# CSI_TX_IF0_CP_INTD_CFG_INTD_CFG register map
Vendor: Texas Instruments
Peripheral module from a debugger description file (folder J7ES).
Registers are 32-bit, access not given, reset values left out (the file's numbers can be read two ways) unless marked. A register's access mark holds for its fields unless they carry their own. Offsets are as the file gives them; lines under a group give offsets from that group; [hi:lo] are bit positions; {n}, {i} and the like mark numbered series; 'fields as' and 'values as' point back to an identical list; <NAME> marks a mode.

## CSI_TX_IF0_CP_INTD_CFG_INTD_CFG
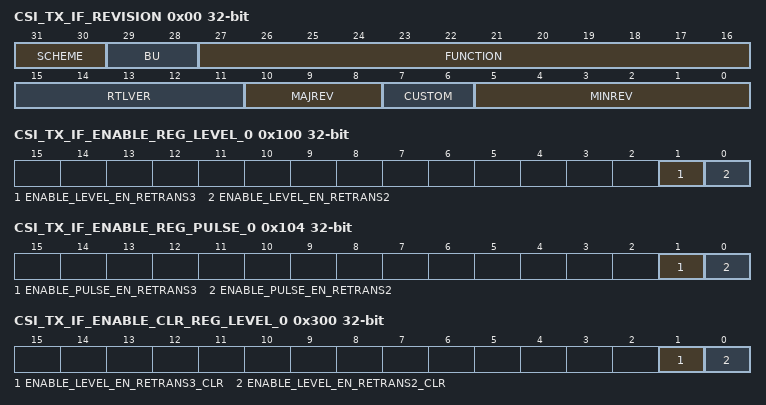
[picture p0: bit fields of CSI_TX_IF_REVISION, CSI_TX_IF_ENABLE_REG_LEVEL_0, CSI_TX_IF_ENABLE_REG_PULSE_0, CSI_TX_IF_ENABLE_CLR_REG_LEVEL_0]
0x00 CSI_TX_IF_REVISION ro — Revision Register
  [31:30] SCHEME
  [29:28] BU
  [27:16] FUNCTION — Module ID
  [15:11] RTLVER — RTL revisions
  [10:8] MAJREV — Major
  [7:6] CUSTOM
  [5:0] MINREV — Minor
0x10 CSI_TX_IF_EOI_REG rw — End of Interrupt Register The EOI register is used to re-trigger the pulse interrupt signal to ensure that any nested interrupt events are serviced. The software interrupt handler must write to the EOI register at the end of the current interrupt processing routine, so that new events can re-trigger the pulse interrupt signal again. For level interrupt signals the EOI register is not functional and must not be used.
  [7:0] EOI_VECTOR — End of Interrupt Vector
0x14 CSI_TX_IF_INTR_VECTOR_REG ro — Interrupt Vector Register
  [31:0] INTR_VECTOR
0x100 CSI_TX_IF_ENABLE_REG_LEVEL_0 — Enable Register 0
  [1] ENABLE_LEVEL_EN_RETRANS3 — Enable Set for level_en_retrans3 (access RW1S)
  [0] ENABLE_LEVEL_EN_RETRANS2 — Enable Set for level_en_retrans2 (access RW1S)
0x104 CSI_TX_IF_ENABLE_REG_PULSE_0 — Enable Register 1
  [1] ENABLE_PULSE_EN_RETRANS3 — Enable Set for pulse_en_retrans3 (access RW1S)
  [0] ENABLE_PULSE_EN_RETRANS2 — Enable Set for pulse_en_retrans2 (access RW1S)
0x300 CSI_TX_IF_ENABLE_CLR_REG_LEVEL_0 — Enable Clear Register 0
  [1] ENABLE_LEVEL_EN_RETRANS3_CLR — Enable Clear for level_en_retrans3 (access RW1C)
  [0] ENABLE_LEVEL_EN_RETRANS2_CLR — Enable Clear for level_en_retrans2 (access RW1C)
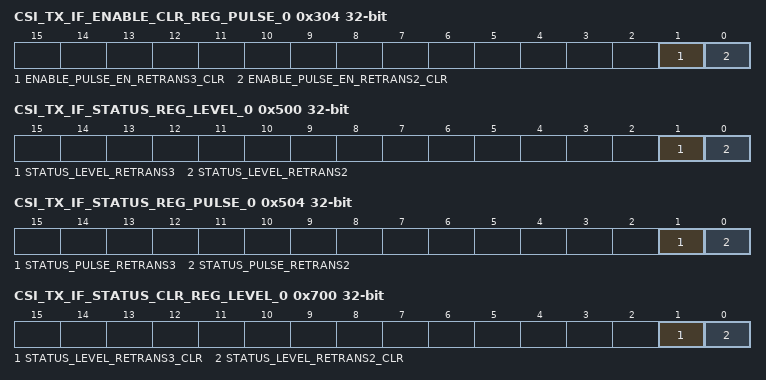
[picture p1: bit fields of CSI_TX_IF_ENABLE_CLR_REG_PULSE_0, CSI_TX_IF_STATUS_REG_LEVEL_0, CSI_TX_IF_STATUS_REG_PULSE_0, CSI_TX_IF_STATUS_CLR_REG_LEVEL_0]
0x304 CSI_TX_IF_ENABLE_CLR_REG_PULSE_0 — Enable Clear Register 1
  [1] ENABLE_PULSE_EN_RETRANS3_CLR — Enable Clear for pulse_en_retrans3 (access RW1C)
  [0] ENABLE_PULSE_EN_RETRANS2_CLR — Enable Clear for pulse_en_retrans2 (access RW1C)
0x500 CSI_TX_IF_STATUS_REG_LEVEL_0 — Status Register 0
  [1] STATUS_LEVEL_RETRANS3 — Status ,write 1 to set, for level_en_retrans3 (access RW1S)
  [0] STATUS_LEVEL_RETRANS2 — Status ,write 1 to set, for level_en_retrans2 (access RW1S)
0x504 CSI_TX_IF_STATUS_REG_PULSE_0 — Status Register 1
  [1] STATUS_PULSE_RETRANS3 — Status ,write 1 to set, for pulse_en_retrans3 (access RW1S)
  [0] STATUS_PULSE_RETRANS2 — Status ,write 1 to set, for pulse_en_retrans2 (access RW1S)
0x700 CSI_TX_IF_STATUS_CLR_REG_LEVEL_0 — Status Clear Register 0
  [1] STATUS_LEVEL_RETRANS3_CLR — Status ,write 1 to clear, for level_en_retrans3 (access RW1C)
  [0] STATUS_LEVEL_RETRANS2_CLR — Status ,write 1 to clear, for level_en_retrans2 (access RW1C)
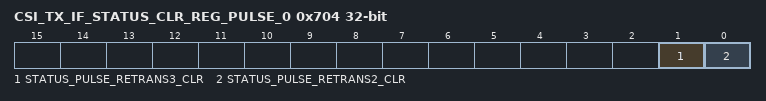
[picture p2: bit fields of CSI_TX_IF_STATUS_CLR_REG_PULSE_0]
0x704 CSI_TX_IF_STATUS_CLR_REG_PULSE_0 — Status Clear Register 1
  [1] STATUS_PULSE_RETRANS3_CLR — Status ,write 1 to clear, for pulse_en_retrans3 (access RW1C)
  [0] STATUS_PULSE_RETRANS2_CLR — Status ,write 1 to clear, for pulse_en_retrans2 (access RW1C)
0xA80 CSI_TX_IF_INTR_VECTOR_REG_LEVEL ro — Interrupt Vector for level
  [31:0] INTR_VECTOR_LEVEL — Interrupt Vector
0xA84 CSI_TX_IF_INTR_VECTOR_REG_PULSE ro — Interrupt Vector for pulse
  [31:0] INTR_VECTOR_PULSE — Interrupt Vector
